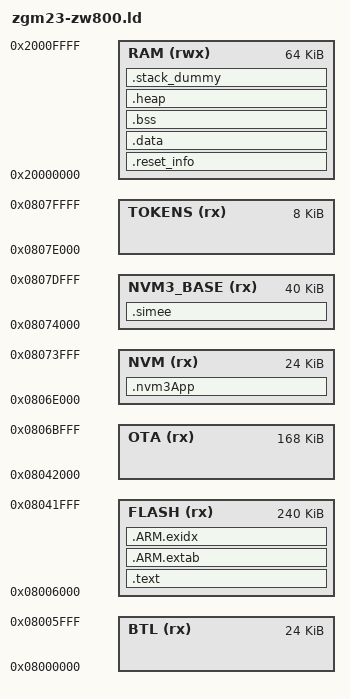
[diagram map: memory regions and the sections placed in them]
/***************************************************************************//**
 * @file
 * Linker script for Silicon Labs ZGM230S devices
 * @version INTERNAL_ec73e54c1d095fa7b814a2883e7d2a21db6311cd
 *******************************************************************************
 * # License
 * <b>Copyright 2019 Silicon Laboratories, Inc. www.silabs.com </b>
 *******************************************************************************
 *
 * SPDX-License-Identifier: Zlib
 * 
 * The licensor of this software is Silicon Laboratories Inc.
 * 
 * This software is provided 'as-is', without any express or implied
 * warranty. In no event will the authors be held liable for any damages
 * arising from the use of this software.
 * 
 * Permission is granted to anyone to use this software for any purpose,
 * including commercial applications, and to alter it and redistribute it
 * freely, subject to the following restrictions:
 * 
 * 1. The origin of this software must not be misrepresented; you must not
 *    claim that you wrote the original software. If you use this software
 *    in a product, an acknowledgment in the product documentation would be
 *    appreciated but is not required.
 * 2. Altered source versions must be plainly marked as such, and must not be
 *    misrepresented as being the original software.
 * 3. This notice may not be removed or altered from any source distribution.
 *
 ******************************************************************************/
/*
*FLASH layout
* -------- 0x08000000 BOOTLOADER           size = 24K  ------
* -------- 0x08006000 Z-Wave image         size = 240K ------
* -------  0x08042000 OTA image            size = 168K ------
* -------  0x0806C000 GAP                  size = 8K   ------ 
* -------  0x0806E000 FS (NVM + NVM3_BASE) size = 64K  ------
* -------  0x0807E000 TOKENS               size = 8K   ------
*/

MEMORY
{
  BTL   (rx) : ORIGIN = 0x08000000, LENGTH = 24K
  FLASH (rx) : ORIGIN = 0x08006000, LENGTH = 240K
  OTA   (rx) : ORIGIN = 0x08042000, LENGTH = 168K
  NVM   (rx) : ORIGIN = 0x0806E000, LENGTH = 24K
  NVM3_BASE (rx) : ORIGIN = 0x08074000, LENGTH = 40K
  TOKENS    (rx) : ORIGIN = 0x0807E000, LENGTH = 8K
  RAM (rwx)  : ORIGIN = 0x20000000, LENGTH = 64K
}

/* Linker script to place sections and symbol values. Should be used together
 * with other linker script that defines memory regions FLASH and RAM.
 * It references following symbols, which must be defined in code:
 *   Reset_Handler : Entry of reset handler
 *
 * It defines following symbols, which code can use without definition:
 *   __exidx_start
 *   __exidx_end
 *   __copy_table_start__
 *   __copy_table_end__
 *   __zero_table_start__
 *   __zero_table_end__
 *   __etext
 *   __data_start__
 *   __preinit_array_start
 *   __preinit_array_end
 *   __init_array_start
 *   __init_array_end
 *   __fini_array_start
 *   __fini_array_end
 *   __data_end__
 *   __bss_start__
 *   __bss_end__
 *   __end__
 *   end
 *   __HeapLimit
 *   __StackLimit
 *   __StackTop
 *   __stack
 *   __Vectors_End
 *   __Vectors_Size
 */
ENTRY(Reset_Handler)

SECTIONS
{

  .nvm3App (NOLOAD):
  {
    . = ALIGN(2048);
    _nvm3App = . ;
    KEEP(*(.nvm3App))
    _envm3App = . ;
  } >NVM

  .simee (NOLOAD):
  {
    . = ALIGN(2048);
    _simee = . ;
    KEEP(*(.simee))
    _esimee = . ;
  } >NVM3_BASE



  .text :
  {
    KEEP(*(.vectors))
    __Vectors_End = .;
    __Vectors_Size = __Vectors_End - __Vectors;
    __end__ = .;

    *(.text*)

    KEEP(*(.init))
    KEEP(*(.fini))

    /* .ctors */
    *crtbegin.o(.ctors)
    *crtbegin?.o(.ctors)
    *(EXCLUDE_FILE(*crtend?.o *crtend.o) .ctors)
    *(SORT(.ctors.*))
    *(.ctors)

    /* .dtors */
    *crtbegin.o(.dtors)
    *crtbegin?.o(.dtors)
    *(EXCLUDE_FILE(*crtend?.o *crtend.o) .dtors)
    *(SORT(.dtors.*))
    *(.dtors)

    *(.rodata*)

    KEEP(*(.eh_frame*))
    KEEP(*(.rodata.app_properties))

    /*We need to calculate the size of the cc_handlers to calculate the total FLASH space used*/
    /*This is useful to make an assert if the total FLASH space used is bigger than the FLASH max size*/
    __start__cc_handlers_v3 = .;
    KEEP(*(_cc_handlers_v3*))
    __stop__cc_handlers_v3 = .;
  } > FLASH

  .ARM.extab :
  {
    *(.ARM.extab* .gnu.linkonce.armextab.*)
  } > FLASH

  __exidx_start = .;
  .ARM.exidx :
  {
    *(.ARM.exidx* .gnu.linkonce.armexidx.*)
  } > FLASH
  __exidx_end = .;

  /* To copy multiple ROM to RAM sections,
   * uncomment .copy.table section and,
   * define __STARTUP_COPY_MULTIPLE in startup_ARMCMx.S */
  /*
  .copy.table :
  {
    . = ALIGN(4);
    __copy_table_start__ = .;
    LONG (__etext)
    LONG (__data_start__)
    LONG (__data_end__ - __data_start__)
    LONG (__etext2)
    LONG (__data2_start__)
    LONG (__data2_end__ - __data2_start__)
    __copy_table_end__ = .;
  } > FLASH
  */

  /* To clear multiple BSS sections,
   * uncomment .zero.table section and,
   * define __STARTUP_CLEAR_BSS_MULTIPLE in startup_ARMCMx.S */
  /*
  .zero.table :
  {
    . = ALIGN(4);
    __zero_table_start__ = .;
    LONG (__bss_start__)
    LONG (__bss_end__ - __bss_start__)
    LONG (__bss2_start__)
    LONG (__bss2_end__ - __bss2_start__)
    __zero_table_end__ = .;
  } > FLASH
  */

  __etext = .;
 
  .reset_info (NOLOAD): {
        *(.data.reset_info)
  } > RAM

  .data : AT (__etext)
  {
    __data_start__ = .;
    *(vtable)
    *(.data*)
    . = ALIGN (4);
    PROVIDE (__ram_func_section_start = .);
    *(.ram)
    PROVIDE (__ram_func_section_end = .);

    . = ALIGN(4);
    /* preinit data */
    PROVIDE_HIDDEN (__preinit_array_start = .);
    KEEP(*(.preinit_array))
    PROVIDE_HIDDEN (__preinit_array_end = .);

    . = ALIGN(4);
    /* init data */
    PROVIDE_HIDDEN (__init_array_start = .);
    KEEP(*(SORT(.init_array.*)))
    KEEP(*(.init_array))
    PROVIDE_HIDDEN (__init_array_end = .);

    . = ALIGN(4);
    /* finit data */
    PROVIDE_HIDDEN (__fini_array_start = .);
    KEEP(*(SORT(.fini_array.*)))
    KEEP(*(.fini_array))
    PROVIDE_HIDDEN (__fini_array_end = .);

    KEEP(*(.jcr*))
    . = ALIGN(4);
    /* All data end */
    __data_end__ = .;

  } > RAM

  .bss :
  {
    . = ALIGN(4);
    __bss_start__ = .;
    *(.bss*)
    *(COMMON)
    . = ALIGN(4);
    __bss_end__ = .;
  } > RAM

  .heap (COPY):
  {
    __HeapBase = .;
    __end__ = .;
    end = __end__;
    _end = __end__;
    KEEP(*(.heap*))
    __HeapLimit = .;
  } > RAM

  /* .stack_dummy section doesn't contains any symbols. It is only
   * used for linker to calculate size of stack sections, and assign
   * values to stack symbols later */
  .stack_dummy (COPY):
  {
    KEEP(*(.stack*))
  } > RAM

  /* Set stack top to end of RAM, and stack limit move down by
   * size of stack_dummy section */
  __StackTop = ORIGIN(RAM) + LENGTH(RAM);
  __StackLimit = __StackTop - SIZEOF(.stack_dummy);
  PROVIDE(__stack = __StackTop);

  /* Check if data + heap + stack exceeds RAM limit */
  ASSERT(__StackLimit >= __HeapLimit, "region RAM overflowed with stack")

  /* Check if FLASH usage exceeds FLASH size */
  ASSERT( LENGTH(FLASH) >= ((__etext - ORIGIN(FLASH) ) + SIZEOF(.data)), "FLASH memory overflowed !")
}
